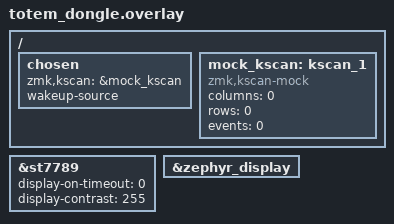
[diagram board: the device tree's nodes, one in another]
/*
 * Dongle overlay – display brightness fix
 */

#include "totem.dtsi"

&st7789 {
    status = "okay";

    display-on-timeout = <0>;

    display-contrast = <255>;
};

&zephyr_display {
    status = "okay";
};

/ {
    chosen {
        zmk,kscan = &mock_kscan;
        wakeup-source;
    };

    mock_kscan: kscan_1 {
        compatible = "zmk,kscan-mock";
        columns = <0>;
        rows = <0>;
        events = <0>;
    };
};
